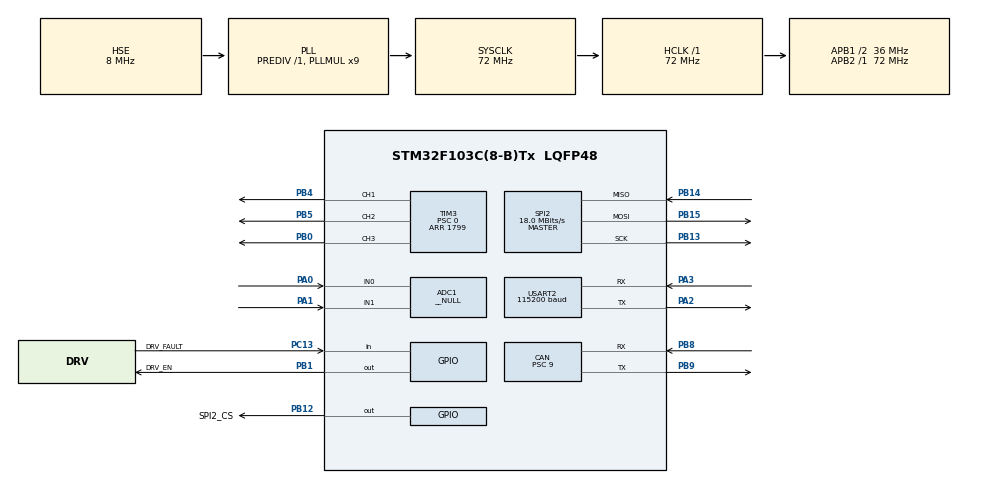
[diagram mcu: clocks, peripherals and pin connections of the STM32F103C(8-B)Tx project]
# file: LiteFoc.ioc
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ADC1.Channel-7\#ChannelRegularConversion=ADC_CHANNEL_0
ADC1.Channel-8\#ChannelRegularConversion=ADC_CHANNEL_1
ADC1.ContinuousConvMode=ENABLE
ADC1.DataAlign=ADC_DATAALIGN_RIGHT
ADC1.EnableInjectedConversion=DISABLE
ADC1.EnableRegularConversion=ENABLE
ADC1.ExternalTrigInjecConv=ADC_INJECTED_SOFTWARE_START
ADC1.InjNumberOfConversion=2
ADC1.Mode=__NULL
ADC1.NbrOfConversion=2
ADC1.NbrOfConversionFlag=1
ADC1.Rank-7\#ChannelRegularConversion=1
ADC1.Rank-8\#ChannelRegularConversion=2
ADC1.SamplingTime-7\#ChannelRegularConversion=ADC_SAMPLETIME_55CYCLES_5
ADC1.SamplingTime-8\#ChannelRegularConversion=ADC_SAMPLETIME_55CYCLES_5
ADC1.master=1
CAN.BS1=CAN_BS1_6TQ
CAN.CalculateBaudRate=500000
CAN.CalculateTimeBit=2000
CAN.CalculateTimeQuantum=250.0
CAN.Prescaler=9
Dma.ADC1.0.Direction=DMA_PERIPH_TO_MEMORY
Dma.ADC1.0.Instance=DMA1_Channel1
Dma.ADC1.0.MemDataAlignment=DMA_MDATAALIGN_HALFWORD
Dma.ADC1.0.MemInc=DMA_MINC_ENABLE
Dma.ADC1.0.Mode=DMA_CIRCULAR
Dma.ADC1.0.PeriphDataAlignment=DMA_PDATAALIGN_HALFWORD
Dma.ADC1.0.PeriphInc=DMA_PINC_DISABLE
Dma.ADC1.0.Priority=DMA_PRIORITY_HIGH
Dma.Request0=ADC1
Dma.Request1=USART2_RX
Dma.Request2=USART2_TX
Dma.USART2_RX.1.Direction=DMA_PERIPH_TO_MEMORY
Dma.USART2_RX.1.Instance=DMA1_Channel6
Dma.USART2_RX.1.MemDataAlignment=DMA_MDATAALIGN_BYTE
Dma.USART2_RX.1.MemInc=DMA_MINC_ENABLE
Dma.USART2_RX.1.Mode=DMA_CIRCULAR
Dma.USART2_RX.1.PeriphDataAlignment=DMA_PDATAALIGN_BYTE
Dma.USART2_RX.1.PeriphInc=DMA_PINC_DISABLE
Dma.USART2_RX.1.Priority=DMA_PRIORITY_VERY_HIGH
Dma.USART2_TX.2.Direction=DMA_MEMORY_TO_PERIPH
Dma.USART2_TX.2.Instance=DMA1_Channel7
Dma.USART2_TX.2.MemDataAlignment=DMA_MDATAALIGN_BYTE
Dma.USART2_TX.2.MemInc=DMA_MINC_ENABLE
Dma.USART2_TX.2.Mode=DMA_NORMAL
Dma.USART2_TX.2.PeriphDataAlignment=DMA_PDATAALIGN_BYTE
Dma.USART2_TX.2.PeriphInc=DMA_PINC_DISABLE
Dma.USART2_TX.2.Priority=DMA_PRIORITY_HIGH
Mcu.Family=STM32F1
Mcu.Name=STM32F103C(8-B)Tx
Mcu.Package=LQFP48
NVIC.CAN1_RX1_IRQn=true\:0\:0\:false\:false\:true\:true\:true\:true
NVIC.CAN1_SCE_IRQn=true\:0\:0\:false\:false\:true\:true\:true\:true
NVIC.DMA1_Channel1_IRQn=true\:0\:0\:false\:false\:true\:false\:true\:true
NVIC.DMA1_Channel6_IRQn=true\:0\:0\:false\:false\:true\:false\:true\:true
NVIC.DMA1_Channel7_IRQn=true\:0\:0\:false\:false\:true\:false\:true\:true
NVIC.PriorityGroup=NVIC_PRIORITYGROUP_4
NVIC.SPI2_IRQn=true\:0\:0\:false\:false\:true\:true\:true\:true
NVIC.TIM4_IRQn=true\:0\:0\:false\:false\:true\:true\:true\:true
NVIC.USART2_IRQn=true\:0\:0\:false\:false\:true\:true\:true\:true
NVIC.USB_HP_CAN1_TX_IRQn=true\:0\:0\:false\:false\:true\:true\:true\:true
NVIC.USB_LP_CAN1_RX0_IRQn=true\:0\:0\:false\:false\:true\:true\:true\:true
PA0-WKUP.Signal=SharedAnalog_PA0
PA1.Signal=SharedAnalog_PA1
PA13.Mode=Serial_Wire
PA13.Signal=SYS_JTMS-SWDIO
PA14.Mode=Serial_Wire
PA14.Signal=SYS_JTCK-SWCLK
PA2.Mode=Asynchronous
PA2.Signal=USART2_TX
PA3.Mode=Asynchronous
PA3.Signal=USART2_RX
PB0.Signal=S_TIM3_CH3
PB1.GPIO_Label=DRV_EN
PB1.Signal=GPIO_Output
PB12.GPIO_Label=SPI2_CS
PB12.Signal=GPIO_Output
PB13.Mode=Full_Duplex_Master
PB13.Signal=SPI2_SCK
PB14.Mode=Full_Duplex_Master
PB14.Signal=SPI2_MISO
PB15.Mode=Full_Duplex_Master
PB15.Signal=SPI2_MOSI
PB4.Signal=S_TIM3_CH1
PB5.Signal=S_TIM3_CH2
PB8.Mode=CAN_Activate
PB8.Signal=CAN_RX
PB9.Mode=CAN_Activate
PB9.Signal=CAN_TX
PC13-TAMPER-RTC.GPIO_Label=DRV_FAULT
PC13-TAMPER-RTC.Signal=GPIO_Input
PD0-OSC_IN.Mode=HSE-External-Oscillator
PD0-OSC_IN.Signal=RCC_OSC_IN
PD1-OSC_OUT.Mode=HSE-External-Oscillator
PD1-OSC_OUT.Signal=RCC_OSC_OUT
ProjectManager.HeapSize=0x200
ProjectManager.StackSize=0x400
ProjectManager.TargetToolchain=Makefile
RCC.ADCPresc=RCC_ADCPCLK2_DIV6
RCC.AHBFreq_Value=72000000
RCC.APB1CLKDivider=RCC_HCLK_DIV2
RCC.APB1Freq_Value=36000000
RCC.APB1TimFreq_Value=72000000
RCC.APB2Freq_Value=72000000
RCC.APB2TimFreq_Value=72000000
RCC.HCLKFreq_Value=72000000
RCC.PLLMUL=RCC_PLL_MUL9
RCC.PLLSourceVirtual=RCC_PLLSOURCE_HSE
RCC.SYSCLKFreq_VALUE=72000000
RCC.SYSCLKSource=RCC_SYSCLKSOURCE_PLLCLK
RCC.USBFreq_Value=72000000
SH.S_TIM3_CH1.0=TIM3_CH1,PWM Generation1 CH1
SH.S_TIM3_CH2.0=TIM3_CH2,PWM Generation2 CH2
SH.S_TIM3_CH3.0=TIM3_CH3,PWM Generation3 CH3
SH.SharedAnalog_PA0.0=GPIO_Analog
SH.SharedAnalog_PA0.1=ADC1_IN0,IN0
SH.SharedAnalog_PA1.0=GPIO_Analog
SH.SharedAnalog_PA1.1=ADC1_IN1,IN1
SPI2.BaudRatePrescaler=SPI_BAUDRATEPRESCALER_2
SPI2.CLKPhase=SPI_PHASE_2EDGE
SPI2.CLKPolarity=SPI_POLARITY_HIGH
SPI2.CalculateBaudRate=18.0 MBits/s
SPI2.DataSize=SPI_DATASIZE_16BIT
SPI2.Direction=SPI_DIRECTION_2LINES
SPI2.Mode=SPI_MODE_MASTER
SPI2.VirtualType=VM_MASTER
TIM3.Channel-PWM\ Generation1\ CH1=TIM_CHANNEL_1
TIM3.Channel-PWM\ Generation2\ CH2=TIM_CHANNEL_2
TIM3.Channel-PWM\ Generation3\ CH3=TIM_CHANNEL_3
TIM3.CounterMode=TIM_COUNTERMODE_CENTERALIGNED1
TIM3.OCFastMode_PWM-PWM\ Generation1\ CH1=TIM_OCFAST_DISABLE
TIM3.Period=1799
TIM3.Prescaler=0
TIM3.TIM_MasterOutputTrigger=TIM_TRGO_RESET
TIM3.TIM_MasterSlaveMode=TIM_MASTERSLAVEMODE_DISABLE
TIM4.AutoReloadPreload=TIM_AUTORELOAD_PRELOAD_ENABLE
TIM4.Period=500-1
TIM4.Prescaler=72-1
USART2.BaudRate=115200
USART2.VirtualMode=VM_ASYNC
VP_TIM4_VS_ClockSourceITR.Mode=TriggerSource_ITR0
board=custom

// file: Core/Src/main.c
/* USER CODE BEGIN Header */
/**
  ******************************************************************************
  * @file           : main.c
  * @brief          : Main program body
  ******************************************************************************
  * @attention
  *
  * Copyright (c) 2025 STMicroelectronics.
  * All rights reserved.
  *
  * This software is licensed under terms that can be found in the LICENSE file
  * in the root directory of this software component.
  * If no LICENSE file comes with this software, it is provided AS-IS.
  *
  ******************************************************************************
  */
/* USER CODE END Header */
#include "main.h"
#include "adc.h"
#include "can.h"
#include "dma.h"
#include "spi.h"
#include "tim.h"
#include "usart.h"
#include "gpio.h"

/* USER CODE BEGIN Includes */
#include "common.h"
/* USER CODE END Includes */

void SystemClock_Config(void);

int main(void)
{

  /* MCU Configuration--------------------------------------------------------*/

  /* Reset of all peripherals, Initializes the Flash interface and the Systick. */
  HAL_Init();

  /* Configure the system clock */
  SystemClock_Config();

  /* Initialize all configured peripherals */
  MX_GPIO_Init();
  MX_DMA_Init();
  MX_USART2_UART_Init();
  MX_ADC1_Init();
  MX_CAN_Init();
  MX_SPI2_Init();
  MX_TIM3_Init();
  MX_TIM4_Init();
  /* USER CODE BEGIN 2 */
  Main();
  /* USER CODE END 2 */

  /* Infinite loop */
  while (1)
  {

  }
}

void SystemClock_Config(void)
{
  RCC_OscInitTypeDef RCC_OscInitStruct = {0};
  RCC_ClkInitTypeDef RCC_ClkInitStruct = {0};
  RCC_PeriphCLKInitTypeDef PeriphClkInit = {0};

  /** Initializes the RCC Oscillators according to the specified parameters
  * in the RCC_OscInitTypeDef structure.
  */
  RCC_OscInitStruct.OscillatorType = RCC_OSCILLATORTYPE_HSE;
  RCC_OscInitStruct.HSEState = RCC_HSE_ON;
  RCC_OscInitStruct.HSEPredivValue = RCC_HSE_PREDIV_DIV1;
  RCC_OscInitStruct.HSIState = RCC_HSI_ON;
  RCC_OscInitStruct.PLL.PLLState = RCC_PLL_ON;
  RCC_OscInitStruct.PLL.PLLSource = RCC_PLLSOURCE_HSE;
  RCC_OscInitStruct.PLL.PLLMUL = RCC_PLL_MUL9;
  if (HAL_RCC_OscConfig(&RCC_OscInitStruct) != HAL_OK)
  {
    Error_Handler();
  }

  /** Initializes the CPU, AHB and APB buses clocks
  */
  RCC_ClkInitStruct.ClockType = RCC_CLOCKTYPE_HCLK|RCC_CLOCKTYPE_SYSCLK
                              |RCC_CLOCKTYPE_PCLK1|RCC_CLOCKTYPE_PCLK2;
  RCC_ClkInitStruct.SYSCLKSource = RCC_SYSCLKSOURCE_PLLCLK;
  RCC_ClkInitStruct.AHBCLKDivider = RCC_SYSCLK_DIV1;
  RCC_ClkInitStruct.APB1CLKDivider = RCC_HCLK_DIV2;
  RCC_ClkInitStruct.APB2CLKDivider = RCC_HCLK_DIV1;

  if (HAL_RCC_ClockConfig(&RCC_ClkInitStruct, FLASH_LATENCY_2) != HAL_OK)
  {
    Error_Handler();
  }
  PeriphClkInit.PeriphClockSelection = RCC_PERIPHCLK_ADC;
  PeriphClkInit.AdcClockSelection = RCC_ADCPCLK2_DIV6;
  if (HAL_RCCEx_PeriphCLKConfig(&PeriphClkInit) != HAL_OK)
  {
    Error_Handler();
  }
}

void Error_Handler(void)
{
  __disable_irq();
  while (1)
  {
  }
}
